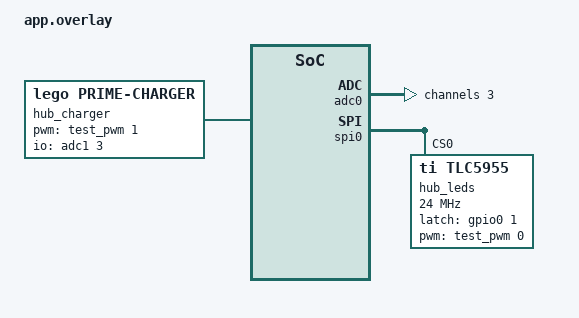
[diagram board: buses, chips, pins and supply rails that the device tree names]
// SPDX-License-Identifier: Apache-2.0
#include <zephyr/dt-bindings/input/input-event-codes.h>
/ {
	test_pwm: test-pwm {
		compatible = "zephyr,fake-pwm";
		#pwm-cells = <2>;
		frequency = <96000000>;
	};
};
adc1: &adc0 {
	ref-internal-mv = <3300>;
	nchannels = <15>;
};
#include "../../boards/lego/spike_prime_f4/buttons.dtsi"
&spi0 {
	hub_leds: test_leds: leds@0 {
		compatible = "ti,tlc5955";
		reg = <0>;
		spi-max-frequency = <24000000>;
		latch-gpios = <&gpio0 1 GPIO_ACTIVE_HIGH>;
		pwms = <&test_pwm 0 104>;
		initial-full-channels = <14>;
	};
};
#include "../../boards/lego/spike_prime_f4/lights.dtsi"

/ {
	hub_charger: charger {
		compatible = "lego,prime-charger";
		mode-controller = <&hub_leds>;
		mode-channel = <14>;
		pwms = <&test_pwm 1 10417>;
		io-channels = <&adc1 3>;
		status-ladder = <&center_keys>;
		status-bit = <2>;
	};
};
&adc1 {
	channel@3 {
		reg = <3>;
		zephyr,gain = "ADC_GAIN_1";
		zephyr,reference = "ADC_REF_INTERNAL";
		zephyr,acquisition-time = <ADC_ACQ_TIME_DEFAULT>;
		zephyr,resolution = <12>;
	};
};
